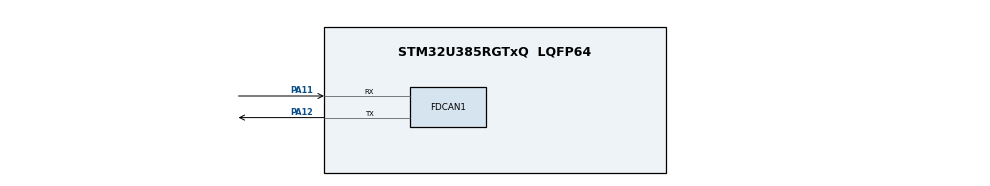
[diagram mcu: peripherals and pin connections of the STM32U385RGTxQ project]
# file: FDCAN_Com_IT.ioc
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CORTEX_M33_NS.userName=CORTEX_M33
FDCAN1.AutoRetransmission=ENABLE
FDCAN1.CalculateBaudRateNominal=1000000
FDCAN1.CalculateTimeBitNominal=1000
FDCAN1.CalculateTimeQuantumNominal=10.416666666666666
FDCAN1.DataPrescaler=1
FDCAN1.DataSyncJumpWidth=3
FDCAN1.DataTimeSeg1=8
FDCAN1.DataTimeSeg2=3
FDCAN1.FrameFormat=FDCAN_FRAME_FD_BRS
FDCAN1.NominalPrescaler=1
FDCAN1.NominalSyncJumpWidth=24
FDCAN1.NominalTimeSeg1=71
FDCAN1.NominalTimeSeg2=24
FDCAN1.StdFiltersNbr=1
FDCAN1.TransmitPause=ENABLE
Mcu.Family=STM32U3
Mcu.Name=STM32U385RGTxQ
Mcu.Package=LQFP64
NVIC.FDCAN1_IT0_IRQn=true\:0\:0\:false\:false\:true\:true\:true\:true
NVIC.PriorityGroup=NVIC_PRIORITYGROUP_4
PA11.Mode=FDCAN_Activate
PA11.Signal=FDCAN1_RX
PA12.Mode=FDCAN_Activate
PA12.Signal=FDCAN1_TX
ProjectManager.HeapSize=0x200
ProjectManager.StackSize=0x400
ProjectManager.TargetToolchain=EWARM V9.20
RCC.ADCFreq_Value=96000000
RCC.AHBFreq_Value=96000000
RCC.APB1Freq_Value=96000000
RCC.APB1TimFreq_Value=96000000
RCC.APB2Freq_Value=96000000
RCC.APB2TimFreq_Value=96000000
RCC.APB3Freq_Value=96000000
RCC.CortexFreq_Value=12000000
RCC.HCLKFreq_Value=96000000
RCC.HSE_VALUE=16000000
RCC.HSI48_VALUE=48000000
RCC.HSI_VALUE=16000000
RCC.LSE_VALUE=32768
RCC.LSIDIV_VALUE=32000
RCC.MSISDIV=RCC_MSI_DIV1
RCC.SYSCLKFreq_VALUE=96000000
RCC.USBFreq_Value=96000000
VP_ICACHE_VS_ICACHE.Mode=DirectMappedCache
VP_PWR_VS_DBSignals.Mode=DisableDeadBatterySignals
VP_PWR_VS_LPOM.Mode=PowerOptimisation
VP_PWR_VS_SECSignals.Mode=Security/Privilege
board=custom

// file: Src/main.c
/* USER CODE BEGIN Header */
/**
  ******************************************************************************
  * @file    FDCAN/FDCAN_Com_IT/Src/main.c
  * @author  MCD Application Team
  * @brief   This sample code shows how to achieve Interrupt Process Communication
  *          between two FDCAN units.
  ******************************************************************************
  * @attention
  *
  * Copyright (c) 2024 STMicroelectronics.
  * All rights reserved.
  *
  * This software is licensed under terms that can be found in the LICENSE file
  * in the root directory of this software component.
  * If no LICENSE file comes with this software, it is provided AS-IS.
  *
  ******************************************************************************
  */
/* USER CODE END Header */
#include "main.h"

/* USER CODE BEGIN PD */
#define TX_ID          (0x111)   /* TX CAN message identifier    */
#define RX_ID          (0x111)   /* RX CAN message identifier    */
/* USER CODE END PD */

/* USER CODE BEGIN PM */
#define COUNTOF(BUFFER) (sizeof((BUFFER)) / sizeof(*(BUFFER)))
/* USER CODE END PM */

FDCAN_HandleTypeDef hfdcan1;

/* USER CODE BEGIN PV */
FDCAN_RxHeaderTypeDef rxHeader;
FDCAN_TxHeaderTypeDef txHeader;
uint8_t rxData[16U];
static const uint8_t txData[] = {0x10, 0x32, 0x54, 0x76, 0x98, 0x00, 0x11, 0x22,
                                 0x33, 0x44, 0x55, 0x66, 0x77, 0x88, 0x99, 0x00
                                };

/* USER CODE END PV */

void SystemClock_Config(void);
static void MX_GPIO_Init(void);
static void MX_FDCAN1_Init(void);
static void MX_ICACHE_Init(void);
/* USER CODE BEGIN PFP */
static uint32_t BufferCmp8b(const uint8_t *pBuffer1, const uint8_t *pBuffer2, uint16_t BufferLength);

/* USER CODE END PFP */

int main(void)
{

  /* USER CODE BEGIN 1 */

  /* STM32U3xx HAL library initialization:
       - Configure the Flash prefetch
       - Configure the Systick to generate an interrupt each 1 msec
       - Set NVIC Group Priority to 3
       - Low Level Initialization
     */
  /* USER CODE END 1 */

  /* MCU Configuration--------------------------------------------------------*/

  /* Reset of all peripherals, Initializes the Flash interface and the Systick. */
  HAL_Init();

  /* Configure the system clock */
  SystemClock_Config();

  /* USER CODE BEGIN SysInit */
  /* Configure LD2 */
  BSP_LED_Init(LD2);

  /* Configure User push-button in interrupt mode */
  BSP_PB_Init(BUTTON_USER, BUTTON_MODE_EXTI);

  /* USER CODE END SysInit */

  /* Initialize all configured peripherals */
  MX_GPIO_Init();
  MX_FDCAN1_Init();
  MX_ICACHE_Init();
  /* USER CODE BEGIN 2 */

  /* Configure reception filter to Rx FIFO 0 */
  FDCAN_FilterTypeDef        sFilterConfig;
  sFilterConfig.IdType       = FDCAN_STANDARD_ID;
  sFilterConfig.FilterIndex  = 0U;
  sFilterConfig.FilterType   = FDCAN_FILTER_MASK;
  sFilterConfig.FilterConfig = FDCAN_FILTER_TO_RXFIFO0;
  sFilterConfig.FilterID1    = TX_ID;
  sFilterConfig.FilterID2    = 0x7FF;
  if (HAL_FDCAN_ConfigFilter(&hfdcan1, &sFilterConfig) != HAL_OK)
  {
    Error_Handler();
  }

  /**
    *  Configure global filter:
    *    - Filter all remote frames with STD and EXT ID
    *    - Reject non matching frames with STD ID and EXT ID
    */
  if (HAL_FDCAN_ConfigGlobalFilter(&hfdcan1,
                                   FDCAN_REJECT, FDCAN_REJECT,
                                   FDCAN_FILTER_REMOTE, FDCAN_FILTER_REMOTE) != HAL_OK)
  {
    Error_Handler();
  }

  /* Activate Rx FIFO 0 new message notification */
  if (HAL_FDCAN_ActivateNotification(&hfdcan1, FDCAN_IT_RX_FIFO0_NEW_MESSAGE, 0U) != HAL_OK)
  {
    Error_Handler();
  }

  /* Prepare Tx message Header */
  txHeader.Identifier          = TX_ID;
  txHeader.IdType              = FDCAN_STANDARD_ID;
  txHeader.TxFrameType         = FDCAN_DATA_FRAME;
  txHeader.DataLength          = FDCAN_DLC_BYTES_16;
  txHeader.ErrorStateIndicator = FDCAN_ESI_ACTIVE;
  txHeader.BitRateSwitch       = FDCAN_BRS_ON;
  txHeader.FDFormat            = FDCAN_FD_CAN;
  txHeader.TxEventFifoControl  = FDCAN_NO_TX_EVENTS;
  txHeader.MessageMarker       = 0U;

  /**
    * Configure and enable Tx Delay Compensation, required for BRS mode.
    * TdcOffset default recommended value: DataTimeSeg1 * DataPrescaler
    * TdcFilter default recommended value: 0
    */
  if (HAL_FDCAN_ConfigTxDelayCompensation(&hfdcan1,
                                          (hfdcan1.Init.DataPrescaler * hfdcan1.Init.DataTimeSeg1), 0U) != HAL_OK)
  {
    Error_Handler();
  }

  if (HAL_FDCAN_EnableTxDelayCompensation(&hfdcan1) != HAL_OK)
  {
    Error_Handler();
  }

  /* Start FDCAN controller */
  if (HAL_FDCAN_Start(&hfdcan1) != HAL_OK)
  {
    Error_Handler();
  }
  /* USER CODE END 2 */

  /* Infinite loop */
  /* USER CODE BEGIN WHILE */
  while (1)
  {
    /* Do nothing here, the reception process is handled in the FDCAN IRQ handler */
    /* USER CODE END WHILE */

  }
}

void SystemClock_Config(void)
{
  RCC_OscInitTypeDef RCC_OscInitStruct = {0};
  RCC_ClkInitTypeDef RCC_ClkInitStruct = {0};

  /** Enable Epod Booster
  */
  if (HAL_RCCEx_EpodBoosterClkConfig(RCC_EPODBOOSTER_SOURCE_MSIS, RCC_EPODBOOSTER_DIV1) != HAL_OK)
  {
    Error_Handler();
  }

  if (HAL_PWREx_EnableEpodBooster() != HAL_OK)
  {
    Error_Handler();
  }

  /** Configure the main internal regulator output voltage
  */
  if (HAL_PWREx_ControlVoltageScaling(PWR_REGULATOR_VOLTAGE_SCALE1) != HAL_OK)
  {
    Error_Handler();
  }

  /** Set Flash latency before increasing MSIS
  */
  __HAL_FLASH_SET_LATENCY(FLASH_LATENCY_2);

  /** Initializes the CPU, AHB and APB buses clocks
  */
  RCC_OscInitStruct.OscillatorType = RCC_OSCILLATORTYPE_MSIS;
  RCC_OscInitStruct.MSISState = RCC_MSI_ON;
  RCC_OscInitStruct.MSISSource = RCC_MSI_RC0;
  RCC_OscInitStruct.MSISDiv = RCC_MSI_DIV1;
  if (HAL_RCC_OscConfig(&RCC_OscInitStruct) != HAL_OK)
  {
    Error_Handler();
  }

  /** Initializes the CPU, AHB and APB buses clocks
  */
  RCC_ClkInitStruct.ClockType = RCC_CLOCKTYPE_HCLK|RCC_CLOCKTYPE_SYSCLK
                              |RCC_CLOCKTYPE_PCLK1|RCC_CLOCKTYPE_PCLK2
                              |RCC_CLOCKTYPE_PCLK3;
  RCC_ClkInitStruct.SYSCLKSource = RCC_SYSCLKSOURCE_MSIS;
  RCC_ClkInitStruct.AHBCLKDivider = RCC_SYSCLK_DIV1;
  RCC_ClkInitStruct.APB1CLKDivider = RCC_HCLK_DIV1;
  RCC_ClkInitStruct.APB2CLKDivider = RCC_HCLK_DIV1;
  RCC_ClkInitStruct.APB3CLKDivider = RCC_HCLK_DIV1;

  if (HAL_RCC_ClockConfig(&RCC_ClkInitStruct, FLASH_LATENCY_2) != HAL_OK)
  {
    Error_Handler();
  }
}

static void MX_FDCAN1_Init(void)
{

  hfdcan1.Instance = FDCAN1;
  hfdcan1.Init.ClockDivider = FDCAN_CLOCK_DIV1;
  hfdcan1.Init.FrameFormat = FDCAN_FRAME_FD_BRS;
  hfdcan1.Init.Mode = FDCAN_MODE_NORMAL;
  hfdcan1.Init.AutoRetransmission = ENABLE;
  hfdcan1.Init.TransmitPause = ENABLE;
  hfdcan1.Init.ProtocolException = DISABLE;
  hfdcan1.Init.NominalPrescaler = 1;
  hfdcan1.Init.NominalSyncJumpWidth = 24;
  hfdcan1.Init.NominalTimeSeg1 = 71;
  hfdcan1.Init.NominalTimeSeg2 = 24;
  hfdcan1.Init.DataPrescaler = 1;
  hfdcan1.Init.DataSyncJumpWidth = 3;
  hfdcan1.Init.DataTimeSeg1 = 8;
  hfdcan1.Init.DataTimeSeg2 = 3;
  hfdcan1.Init.StdFiltersNbr = 1;
  hfdcan1.Init.ExtFiltersNbr = 0;
  hfdcan1.Init.TxFifoQueueMode = FDCAN_TX_FIFO_OPERATION;
  if (HAL_FDCAN_Init(&hfdcan1) != HAL_OK)
  {
    Error_Handler();
  }

}

static void MX_ICACHE_Init(void)
{

  /** Enable instruction cache in 1-way (direct mapped cache)
  */
  if (HAL_ICACHE_ConfigAssociativityMode(ICACHE_1WAY) != HAL_OK)
  {
    Error_Handler();
  }
  if (HAL_ICACHE_Enable() != HAL_OK)
  {
    Error_Handler();
  }

}

static void MX_GPIO_Init(void)
{

  /* GPIO Ports Clock Enable */
  __HAL_RCC_GPIOA_CLK_ENABLE();

}

/* USER CODE BEGIN 4 */

/**
  * @brief  Rx FIFO 0 callback.
  * @param  hfdcan pointer to an FDCAN_HandleTypeDef structure that contains
  *         the configuration information for the specified FDCAN.
  * @param  RxFifo0ITs indicates which Rx FIFO 0 interrupts are signaled.
  *         This parameter can be any combination of @arg FDCAN_Rx_Fifo0_Interrupts.
  */
void HAL_FDCAN_RxFifo0Callback(FDCAN_HandleTypeDef *hfdcan, uint32_t RxFifo0ITs)
{
  if ((RxFifo0ITs & FDCAN_IT_RX_FIFO0_NEW_MESSAGE) != 0U)
  {
    /* Retrieve Rx messages from RX FIFO0 */
    if (HAL_FDCAN_GetRxMessage(hfdcan, FDCAN_RX_FIFO0, &rxHeader, rxData) != HAL_OK)
    {
      Error_Handler();
    }

    /* Compare received RX message to expected data. Ignore if not matching. */
    if ((rxHeader.Identifier == RX_ID) &&
        (rxHeader.IdType     == FDCAN_STANDARD_ID) &&
        (rxHeader.DataLength == FDCAN_DLC_BYTES_16) &&
        (BufferCmp8b(txData, rxData, COUNTOF(rxData)) == 0U))
    {
      /* Turn LD2 on */
      BSP_LED_On(LD2);
    }
  }
}

/**
  * @brief  BSP User push-button callback
  * @param  Button Specifies the pin connected EXTI line
  * @retval None.
  */
void BSP_PB_Callback(Button_TypeDef Button)
{
  if (Button == BUTTON_USER)
  {
    /* Turn LD2 off */
    BSP_LED_Off(LD2);

    /* Add message to TX FIFO */
    if (HAL_FDCAN_AddMessageToTxFifoQ(&hfdcan1, &txHeader, txData) != HAL_OK)
    {
      Error_Handler();
    }

    /* Delay for simple button debounce */
    HAL_Delay(100U);
  }
}

/**
  * @brief  Compares two buffers.
  * @param  pBuffer1 buffer to be compared.
  * @param  pBuffer2 buffer to be compared.
  * @param  BufferLength: buffer's length.
  * @retval 0: pBuffer1 is identical to pBuffer2
  * @retval 1: pBuffer1 differs from pBuffer2
  */
static uint32_t BufferCmp8b(const uint8_t *pBuffer1, const uint8_t *pBuffer2, uint16_t BufferLength)
{
  while (BufferLength--)
  {
    if (*pBuffer1 != *pBuffer2)
    {
      return 1U;
    }

    pBuffer1++;
    pBuffer2++;
  }
  return 0U;
}
/* USER CODE END 4 */

void Error_Handler(void)
{
  /* USER CODE BEGIN Error_Handler_Debug */
  /* User can add his own implementation to report the HAL error return state */

  while (1)
  {
    /* Toggle LD2 on */
    BSP_LED_Toggle(LD2);

    /* 1s delay */
    HAL_Delay(1000U);
  }
  /* USER CODE END Error_Handler_Debug */
}
